# a34g43x register map
Vendor: ABOV Semiconductor Co., Ltd.; File version: 1.0
CPU: CM4 r0p1, little endian, MPU, FPU, VTOR, 4 interrupt priority bits
Registers are 32-bit, read-write, reset 0x0 unless marked. A register's access mark holds for its fields unless they carry their own. Offsets are from the block's base; [hi:lo] are bit positions; {n}, {i} and the like mark numbered series.

## PCU — General Port
Base 0x51010000
Same registers: PA 0x41010000, PB 0x41010100, PC 0x41010200, PD 0x41010300, PE 0x41010400, PF 0x41010500, PG 0x41010600
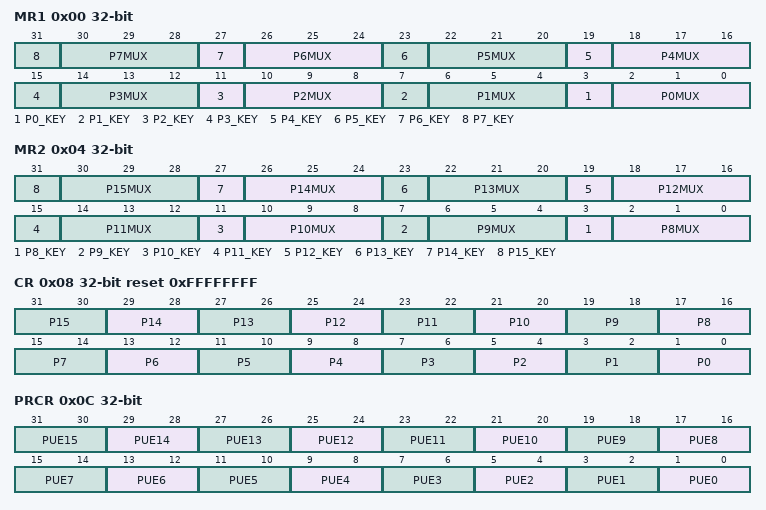
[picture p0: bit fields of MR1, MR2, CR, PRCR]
0x00 MR1 — Port n MUX1 Selection Register
  [4n+3] P{n}_KEY wo (n=0..7) — Pin {n} Mode Selection Access Key
  [4n+2:4n] P{n}MUX (n=0..7) — Pin {n} Mode Selection bits
0x04 MR2 — Port n MUX2 Selection Register
  [4n-29] P{n}_KEY wo (n=8..15) — Pin {n} Mode Selection Access Key
  [4n-30:4n-32] P{n}MUX (n=8..15) — Pin {n} Mode Selection bits
0x08 CR reset 0xFFFFFFFF — Port n Type Selection Register
  [2n+1:2n] P{n} (n=0..15) — Pin {n} Type Selection bit
0x0C PRCR — Port n Pull-up/down Selection Register
  [2n+1:2n] PUE{n} (n=0..15) — Pin {n} Pull-up/down Selection bits
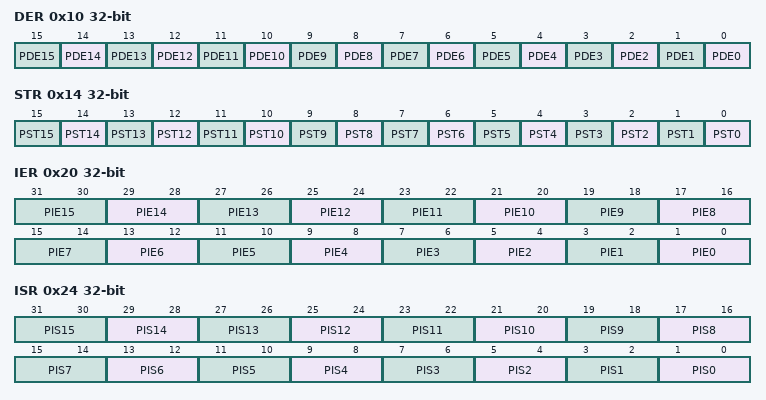
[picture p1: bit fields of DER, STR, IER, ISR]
0x10 DER — Port n Debounce Enable Register
  [n] PDE{n} (n=0..15) — Pin {n} Debounce Enable bits
0x14 STR — Port n Strength Selection Register
  [n] PST{n} (n=0..15) — Pin {n} Strength Selection bit
0x20 IER — Port n Interrupt Enable Register
  [2n+1:2n] PIE{n} (n=0..15) — Pin {n} Interrupt Enable bit
0x24 ISR — Port n Interrupt Status Register
  [2n+1:2n] PIS{n} (n=0..15) — Pin {n} Interrupt Status bit
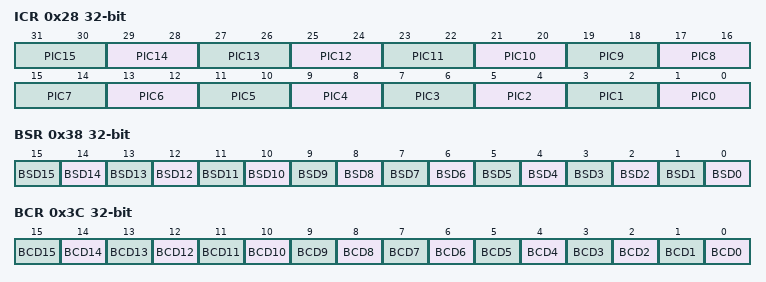
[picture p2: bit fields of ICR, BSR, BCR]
0x28 ICR — Port n Interrupt Control Register
  [2n+1:2n] PIC{n} (n=0..15) — Pin {n} Interrupt Control bit
0x30 ODR — Port n Output Data Register
  [15:0] POD — Pin Output Data bit
0x34 IDR ro — Port n Input Data Register
  [15:0] PID — Port Input Data bits
0x38 BSR wo — Port n Bit Set Register
  [n] BSD{n} (n=0..15) — Port {n} Bit Set bits
0x3C BCR wo — Port n Bit Clear Register
  [n] BCD{n} (n=0..15) — Port {n} Bit Clear bits

## RSTDB — Pin Reset Debounce Control
Base 0x41010F0C
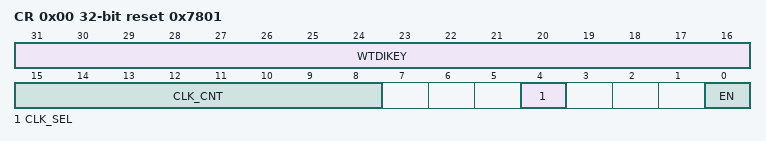
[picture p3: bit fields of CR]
0x00 CR reset 0x7801 — Pin Reset Debounce Control
  [31:16] WTDIKEY wo — Write Identification Key
  [15:8] CLK_CNT — Noise cancel delay option for selected debounce clock
  [4] CLK_SEL — Debounce clock selection Bit
  [0] EN — Pin Reset Debounce Enable Bit

## PORTEN — General Port Access Enable
Base 0x41010FF0
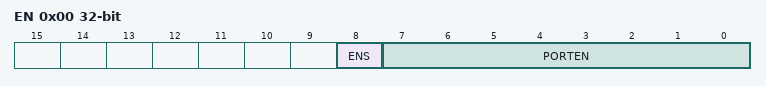
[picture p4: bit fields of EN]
0x00 EN — Port Access Enable Register
  [8] ENS ro — Enable Status Bit
  [7:0] PORTEN — Port Access Enable bit, write sequence 0x15, 0x51

## DFMC — DATA FLASH MEMORY CONTROLLER
Base 0x41001000
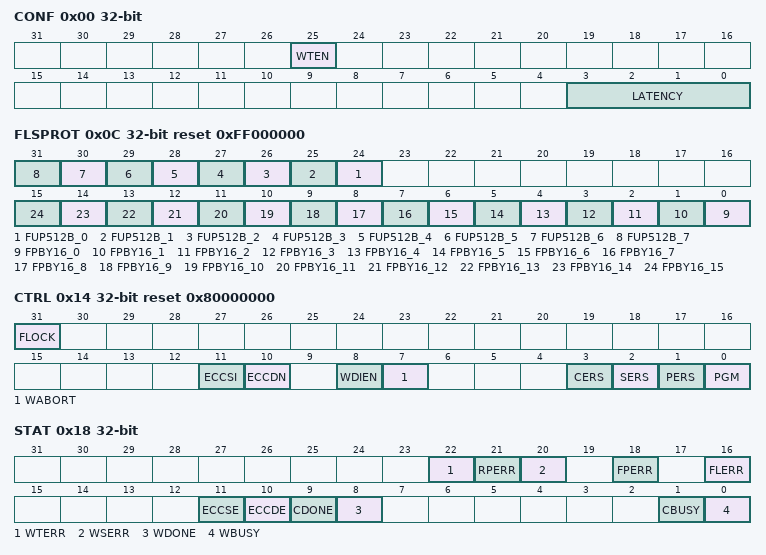
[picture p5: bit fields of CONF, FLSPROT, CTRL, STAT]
0x00 CONF — Data Flash Memory Config Register
  [25] WTEN — Whether to Enable or Disable the Data Flash Write
  [3:0] LATENCY — Flash Wait Value Bits
0x04 FLSKEY wo — Data Flash Memory Access Key Register
  [31:0] FKEY — Flash Memory Access Key, KEY1(0x01234567) -> KEY2(0x12345678) -> KEY3(0x23456789)
0x0C FLSPROT reset 0xFF000000 — Data Flash Memory Protection Register
  [n+24] FUP512B_{n} (n=0..7) — Flash upper 4KB Unprotection
  [n] FPBY16_{n} (n=0..15) — Flash 2KB Protection
0x14 CTRL reset 0x80000000 — Data Flash Access Control Register
  [31] FLOCK — Flash Memory Lock Bit
  [11] ECCSI — Whether to Enable or Disable the ECC Single Error Interrupt
    0=Disable interrupt; 1=Enable interrupt
  [10] ECCDN — Whether to Enable or Disable the ECC Double Error Non-Maskable Interrupt
    0=Disable interrupt; 1=Enable interrupt
  [8] WDIEN — Whether to Enable or Disable the Write Done Interrupt
    0=Disable interrupt; 1=Enable interrupt
  [7] WABORT — Abort write operation
    0=Disable (No Effect); 1=Enable (Abort write operaton)
  [3] CERS — Flash Memory Bulk(Chip) Erase Mode
    0=Disable bulk erase; 1=Enable bulk erase
  [2] SERS — Flash Memory Sector (2KB) Erase Mode
    0=Disable sector erase; 1=Enable sector erase
  [1] PERS — Flash Memory Page (512 Bytes) Erase Mode
    0=Disable page erase; 1=Enable page erase
  [0] PGM — Flash Memory Write Mode
    0=Disable write mode; 1=Enable write mode
0x18 STAT — Data Flash Access Status Register
  [22] WTERR — Wrtie Timeout Error (Cleared by writing a '1' )
  [21] RPERR — Read Protect Error (Cleared by writing a '1' )
  [20] WSERR — Write Sequence Error (Cleared by writing a '1' )
  [18] FPERR — Flash Protect Error (Cleared by writing a '1' )
  [16] FLERR — Flash Lock Error (Cleared by writing a '1' )
  [11] ECCSE — ECC Single Error (Cleared by writing a '1' )
  [10] ECCDE — ECC Double Error (Cleared by writing a '1' )
  [9] CDONE — Checksum Done Check (Cleared by writing a '1' )
  [8] WDONE — Write Done Check (Cleared by writing a '1' )
  [1] CBUSY ro — Checksum Busy Check
    0=Not_Busy (Checksum Not Busy); 1=Busy (Checksum Busy)
  [0] WBUSY ro — Write Busy Check
    0=Not_Busy (Checksum Not Busy); 1=Busy (Checksum Busy)
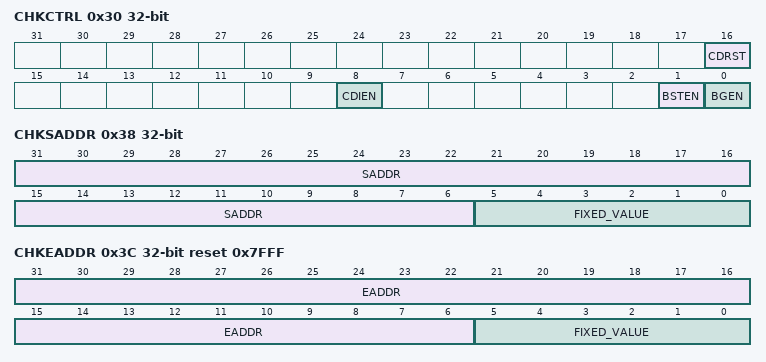
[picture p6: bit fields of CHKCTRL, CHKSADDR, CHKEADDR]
0x30 CHKCTRL — Data Flash Checksum Control Register
  [16] CDRST wo — Checksum Data Reset (Auto Cleared)
    0=No_Effect; 1=Reset
  [8] CDIEN — Checksum Done Interrupt
    0=Disable interrupt; 1=Enable interrupt
  [1] BSTEN wo — Burst Mode
    0=Disable burst mode; 1=Enable burst mode
  [0] BGEN wo — Back Ground Mode
    0=Disable back ground mode; 1=Enable back ground mode
0x34 CHKDOUT ro reset 0xFFFF — Data Flash Checksum Data Output Register
  [15:0] CDOUT — Flash Checksum Data Output bit
0x38 CHKSADDR — Data Flash Checksum Start Address Resgister
  [31:6] SADDR — Flash Checksum Start Address bit
  [5:0] FIXED_VALUE ro — Fixed Vaule
0x3C CHKEADDR reset 0x7FFF — Data Flash Checksum End Address Register
  [31:6] EADDR — Flash Checksum End Address bit
  [5:0] FIXED_VALUE ro
0x40 WTIMEOUT — Data Flash Write Timeout Register
  [31:0] WTIMEOUT — Write timeout count
0x50 ECCEADDR ro — Data Flash ECC Error Address Register
  [31:0] ECCEA — Data Flash ECC Error Address bit
0x54 ECCEDATA ro — Data Flash ECC Error Data Register
  [31:0] ECCED — Data Flash ECC Error Data bit
0x58 ECCEPARITY ro — Data Flash ECC Error Parity Register
  [6:0] ECCEP — Data Flash ECC Error Parity
